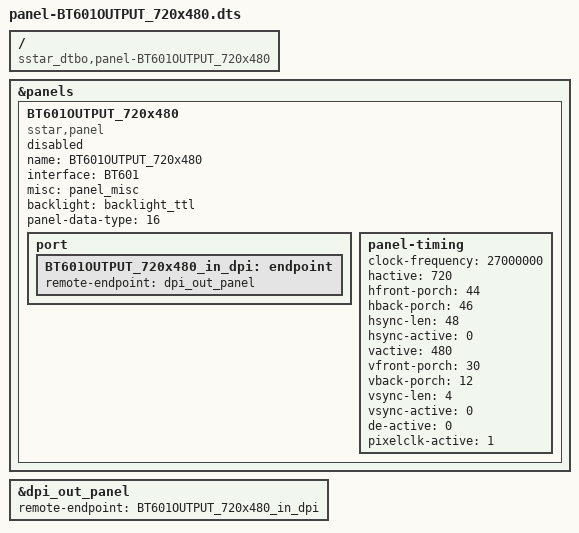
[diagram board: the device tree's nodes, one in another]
/dts-v1/;
/plugin/;

/ {
    compatible = "sstar_dtbo,panel-BT601OUTPUT_720x480";
};

&panels {
    BT601OUTPUT_720x480 {
        compatible = "sstar,panel";
        name = "BT601OUTPUT_720x480";
        interface = "BT601"; /* TTL/MIPI/LVDS/BT1120/BT656/BT601 */
        misc = <&panel_misc>;
        backlight = <&backlight_ttl>;
        panel-data-type = <16>;
        status = "disable";

        port {
            BT601OUTPUT_720x480_in_dpi: endpoint {
                remote-endpoint = <&dpi_out_panel>;
            };
        };

        panel-timing {
            clock-frequency = <27000000>;
            hactive = <720>;
            hfront-porch = <44>;
            hback-porch = <46>;
            hsync-len = <48>;
            hsync-active = <0>;
            vactive = <480>;
            vfront-porch = <30>;
            vback-porch = <12>;
            vsync-len = <4>;
            vsync-active = <0>;
            de-active = <0>;
            pixelclk-active = <1>;
        };
    };
};

&dpi_out_panel {
    remote-endpoint = <&BT601OUTPUT_720x480_in_dpi>;
};
